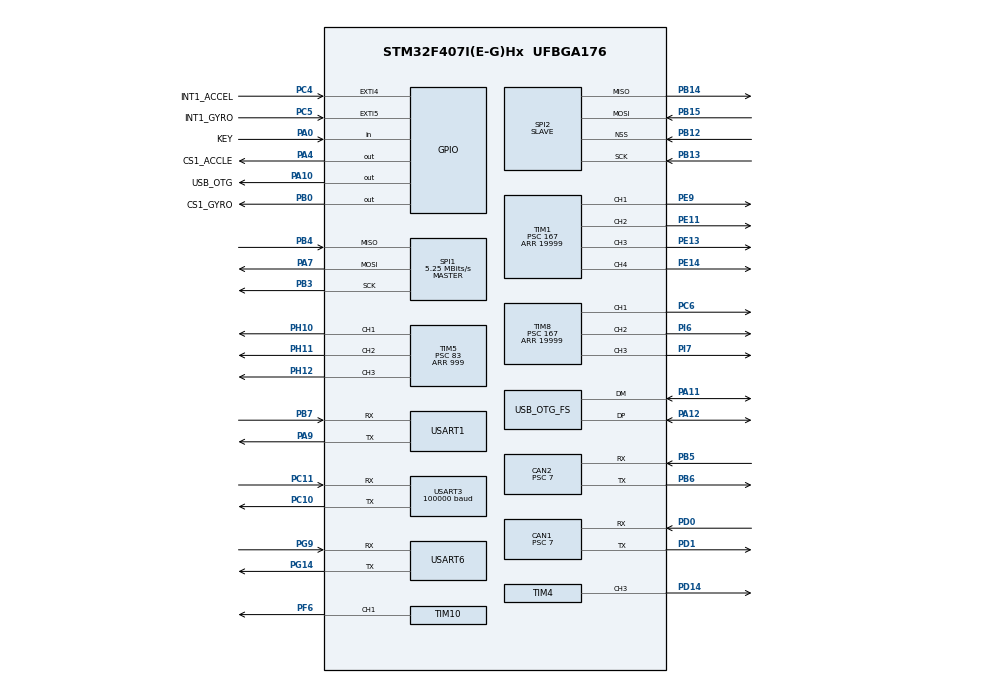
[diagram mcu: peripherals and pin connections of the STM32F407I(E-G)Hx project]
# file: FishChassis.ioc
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CAN1.BS1=CAN_BS1_4TQ
CAN1.CalculateBaudRate=999999
CAN1.CalculateTimeBit=1000
CAN1.CalculateTimeQuantum=166.66666666666669
CAN1.Prescaler=7
CAN2.BS1=CAN_BS1_4TQ
CAN2.CalculateBaudRate=999999
CAN2.CalculateTimeBit=1000
CAN2.CalculateTimeQuantum=166.66666666666669
CAN2.Prescaler=7
Dma.Request0=USART1_RX
Dma.Request1=USART1_TX
Dma.Request2=USART6_RX
Dma.Request3=USART6_TX
Dma.Request4=SPI2_RX
Dma.Request5=SPI2_TX
Dma.Request6=USART3_RX
Dma.SPI2_RX.4.Direction=DMA_PERIPH_TO_MEMORY
Dma.SPI2_RX.4.FIFOMode=DMA_FIFOMODE_DISABLE
Dma.SPI2_RX.4.Instance=DMA1_Stream3
Dma.SPI2_RX.4.MemDataAlignment=DMA_MDATAALIGN_BYTE
Dma.SPI2_RX.4.MemInc=DMA_MINC_ENABLE
Dma.SPI2_RX.4.Mode=DMA_NORMAL
Dma.SPI2_RX.4.PeriphDataAlignment=DMA_PDATAALIGN_BYTE
Dma.SPI2_RX.4.PeriphInc=DMA_PINC_DISABLE
Dma.SPI2_RX.4.Priority=DMA_PRIORITY_LOW
Dma.SPI2_TX.5.Direction=DMA_MEMORY_TO_PERIPH
Dma.SPI2_TX.5.FIFOMode=DMA_FIFOMODE_DISABLE
Dma.SPI2_TX.5.Instance=DMA1_Stream4
Dma.SPI2_TX.5.MemDataAlignment=DMA_MDATAALIGN_BYTE
Dma.SPI2_TX.5.MemInc=DMA_MINC_ENABLE
Dma.SPI2_TX.5.Mode=DMA_NORMAL
Dma.SPI2_TX.5.PeriphDataAlignment=DMA_PDATAALIGN_BYTE
Dma.SPI2_TX.5.PeriphInc=DMA_PINC_DISABLE
Dma.SPI2_TX.5.Priority=DMA_PRIORITY_LOW
Dma.USART1_RX.0.Direction=DMA_PERIPH_TO_MEMORY
Dma.USART1_RX.0.FIFOMode=DMA_FIFOMODE_DISABLE
Dma.USART1_RX.0.Instance=DMA2_Stream2
Dma.USART1_RX.0.MemDataAlignment=DMA_MDATAALIGN_BYTE
Dma.USART1_RX.0.MemInc=DMA_MINC_ENABLE
Dma.USART1_RX.0.Mode=DMA_NORMAL
Dma.USART1_RX.0.PeriphDataAlignment=DMA_PDATAALIGN_BYTE
Dma.USART1_RX.0.PeriphInc=DMA_PINC_DISABLE
Dma.USART1_RX.0.Priority=DMA_PRIORITY_LOW
Dma.USART1_TX.1.Direction=DMA_MEMORY_TO_PERIPH
Dma.USART1_TX.1.FIFOMode=DMA_FIFOMODE_DISABLE
Dma.USART1_TX.1.Instance=DMA2_Stream7
Dma.USART1_TX.1.MemDataAlignment=DMA_MDATAALIGN_BYTE
Dma.USART1_TX.1.MemInc=DMA_MINC_ENABLE
Dma.USART1_TX.1.Mode=DMA_NORMAL
Dma.USART1_TX.1.PeriphDataAlignment=DMA_PDATAALIGN_BYTE
Dma.USART1_TX.1.PeriphInc=DMA_PINC_DISABLE
Dma.USART1_TX.1.Priority=DMA_PRIORITY_LOW
Dma.USART3_RX.6.Direction=DMA_PERIPH_TO_MEMORY
Dma.USART3_RX.6.FIFOMode=DMA_FIFOMODE_DISABLE
Dma.USART3_RX.6.Instance=DMA1_Stream1
Dma.USART3_RX.6.MemDataAlignment=DMA_MDATAALIGN_BYTE
Dma.USART3_RX.6.MemInc=DMA_MINC_ENABLE
Dma.USART3_RX.6.Mode=DMA_NORMAL
Dma.USART3_RX.6.PeriphDataAlignment=DMA_PDATAALIGN_BYTE
Dma.USART3_RX.6.PeriphInc=DMA_PINC_DISABLE
Dma.USART3_RX.6.Priority=DMA_PRIORITY_LOW
Dma.USART6_RX.2.Direction=DMA_PERIPH_TO_MEMORY
Dma.USART6_RX.2.FIFOMode=DMA_FIFOMODE_DISABLE
Dma.USART6_RX.2.Instance=DMA2_Stream1
Dma.USART6_RX.2.MemDataAlignment=DMA_MDATAALIGN_BYTE
Dma.USART6_RX.2.MemInc=DMA_MINC_ENABLE
Dma.USART6_RX.2.Mode=DMA_NORMAL
Dma.USART6_RX.2.PeriphDataAlignment=DMA_PDATAALIGN_BYTE
Dma.USART6_RX.2.PeriphInc=DMA_PINC_DISABLE
Dma.USART6_RX.2.Priority=DMA_PRIORITY_LOW
Dma.USART6_TX.3.Direction=DMA_MEMORY_TO_PERIPH
Dma.USART6_TX.3.FIFOMode=DMA_FIFOMODE_DISABLE
Dma.USART6_TX.3.Instance=DMA2_Stream6
Dma.USART6_TX.3.MemDataAlignment=DMA_MDATAALIGN_BYTE
Dma.USART6_TX.3.MemInc=DMA_MINC_ENABLE
Dma.USART6_TX.3.Mode=DMA_NORMAL
Dma.USART6_TX.3.PeriphDataAlignment=DMA_PDATAALIGN_BYTE
Dma.USART6_TX.3.PeriphInc=DMA_PINC_DISABLE
Dma.USART6_TX.3.Priority=DMA_PRIORITY_LOW
Mcu.Family=STM32F4
Mcu.Name=STM32F407I(E-G)Hx
Mcu.Package=UFBGA176
NVIC.CAN1_RX0_IRQn=true\:0\:0\:false\:false\:true\:false\:true\:true\:true
NVIC.CAN2_RX1_IRQn=true\:0\:0\:false\:false\:true\:false\:true\:true\:true
NVIC.DMA1_Stream1_IRQn=true\:0\:0\:false\:false\:true\:true\:false\:true\:true
NVIC.DMA1_Stream3_IRQn=true\:0\:0\:false\:false\:true\:true\:false\:true\:true
NVIC.DMA1_Stream4_IRQn=true\:0\:0\:false\:false\:true\:true\:false\:true\:true
NVIC.DMA2_Stream1_IRQn=true\:0\:0\:false\:false\:true\:true\:false\:true\:true
NVIC.DMA2_Stream2_IRQn=true\:0\:0\:false\:false\:true\:true\:false\:true\:true
NVIC.DMA2_Stream6_IRQn=true\:0\:0\:false\:false\:true\:true\:false\:true\:true
NVIC.DMA2_Stream7_IRQn=true\:0\:0\:false\:false\:true\:true\:false\:true\:true
NVIC.EXTI4_IRQn=true\:0\:0\:false\:false\:false\:false\:true\:true\:false
NVIC.EXTI9_5_IRQn=true\:0\:0\:false\:false\:false\:false\:true\:true\:false
NVIC.OTG_FS_IRQn=true\:0\:0\:false\:false\:true\:false\:true\:true\:true
NVIC.PriorityGroup=NVIC_PRIORITYGROUP_4
NVIC.SPI2_IRQn=true\:0\:0\:false\:false\:true\:false\:true\:true\:true
NVIC.TIM8_TRG_COM_TIM14_IRQn=true\:15\:0\:false\:false\:false\:false\:false\:true\:true
NVIC.TimeBase=TIM8_TRG_COM_TIM14_IRQn
NVIC.TimeBaseIP=TIM14
NVIC.USART1_IRQn=true\:0\:0\:false\:false\:true\:false\:true\:true\:true
NVIC.USART3_IRQn=true\:0\:0\:false\:false\:true\:false\:true\:true\:true
NVIC.USART6_IRQn=true\:0\:0\:false\:false\:true\:false\:true\:true\:true
PA0-WKUP.GPIO_Label=KEY
PA0-WKUP.Signal=GPIO_Input
PA10.GPIO_Label=USB_OTG
PA10.PinState=GPIO_PIN_SET
PA10.Signal=GPIO_Output
PA11.Mode=Device_Only
PA11.Signal=USB_OTG_FS_DM
PA12.Mode=Device_Only
PA12.Signal=USB_OTG_FS_DP
PA13.Mode=Serial_Wire
PA13.Signal=SYS_JTMS-SWDIO
PA14.Mode=Serial_Wire
PA14.Signal=SYS_JTCK-SWCLK
PA4.GPIO_Label=CS1_ACCLE
PA4.GPIO_PuPd=GPIO_PULLUP
PA4.GPIO_Speed=GPIO_SPEED_FREQ_VERY_HIGH
PA4.PinState=GPIO_PIN_SET
PA4.Signal=GPIO_Output
PA7.Mode=Full_Duplex_Master
PA7.Signal=SPI1_MOSI
PA9.Mode=Asynchronous
PA9.Signal=USART1_TX
PB0.GPIO_Label=CS1_GYRO
PB0.GPIO_PuPd=GPIO_PULLUP
PB0.GPIO_Speed=GPIO_SPEED_FREQ_VERY_HIGH
PB0.PinState=GPIO_PIN_SET
PB0.Signal=GPIO_Output
PB12.Mode=NSS_Signal_Hard_Input
PB12.Signal=SPI2_NSS
PB13.Mode=Full_Duplex_Slave
PB13.Signal=SPI2_SCK
PB14.Mode=Full_Duplex_Slave
PB14.Signal=SPI2_MISO
PB15.Mode=Full_Duplex_Slave
PB15.Signal=SPI2_MOSI
PB3.Mode=Full_Duplex_Master
PB3.Signal=SPI1_SCK
PB4.Mode=Full_Duplex_Master
PB4.Signal=SPI1_MISO
PB5.Mode=CAN_Activate
PB5.Signal=CAN2_RX
PB6.Mode=CAN_Activate
PB6.Signal=CAN2_TX
PB7.Mode=Asynchronous
PB7.Signal=USART1_RX
PC10.Mode=Asynchronous
PC10.Signal=USART3_TX
PC11.Mode=Asynchronous
PC11.Signal=USART3_RX
PC4.GPIO_Label=INT1_ACCEL
PC4.GPIO_ModeDefaultEXTI=GPIO_MODE_IT_FALLING
PC4.Signal=GPXTI4
PC5.GPIO_Label=INT1_GYRO
PC5.GPIO_ModeDefaultEXTI=GPIO_MODE_IT_FALLING
PC5.Signal=GPXTI5
PC6.Signal=S_TIM8_CH1
PD0.Mode=CAN_Activate
PD0.Signal=CAN1_RX
PD1.Mode=CAN_Activate
PD1.Signal=CAN1_TX
PD14.Signal=S_TIM4_CH3
PE11.Signal=S_TIM1_CH2
PE13.Signal=S_TIM1_CH3
PE14.Signal=S_TIM1_CH4
PE9.Signal=S_TIM1_CH1
PF6.Signal=S_TIM10_CH1
PG14.Mode=Asynchronous
PG14.Signal=USART6_TX
PG9.Mode=Asynchronous
PG9.Signal=USART6_RX
PH0-OSC_IN.Mode=HSE-External-Oscillator
PH0-OSC_IN.Signal=RCC_OSC_IN
PH1-OSC_OUT.Mode=HSE-External-Oscillator
PH1-OSC_OUT.Signal=RCC_OSC_OUT
PH10.Signal=S_TIM5_CH1
PH11.Signal=S_TIM5_CH2
PH12.Signal=S_TIM5_CH3
PI6.Signal=S_TIM8_CH2
PI7.Signal=S_TIM8_CH3
ProjectManager.HeapSize=0x200
ProjectManager.StackSize=0x400
ProjectManager.TargetToolchain=STM32CubeIDE
RCC.48MHZClocksFreq_Value=48000000
RCC.AHBFreq_Value=168000000
RCC.APB1CLKDivider=RCC_HCLK_DIV4
RCC.APB1Freq_Value=42000000
RCC.APB1TimFreq_Value=84000000
RCC.APB2CLKDivider=RCC_HCLK_DIV2
RCC.APB2Freq_Value=84000000
RCC.APB2TimFreq_Value=168000000
RCC.CortexFreq_Value=168000000
RCC.HCLKFreq_Value=168000000
RCC.HSE_VALUE=12000000
RCC.HSI_VALUE=16000000
RCC.LSE_VALUE=32768
RCC.PLLM=6
RCC.PLLN=168
RCC.PLLQ=7
RCC.SYSCLKFreq_VALUE=168000000
RCC.SYSCLKSource=RCC_SYSCLKSOURCE_PLLCLK
RCC.VCOOutputFreq_Value=336000000
SH.S_TIM10_CH1.0=TIM10_CH1,PWM Generation1 CH1
SH.S_TIM1_CH1.0=TIM1_CH1,PWM Generation1 CH1
SH.S_TIM1_CH2.0=TIM1_CH2,PWM Generation2 CH2
SH.S_TIM1_CH3.0=TIM1_CH3,PWM Generation3 CH3
SH.S_TIM1_CH4.0=TIM1_CH4,PWM Generation4 CH4
SH.S_TIM4_CH3.0=TIM4_CH3,PWM Generation3 CH3
SH.S_TIM5_CH1.0=TIM5_CH1,PWM Generation1 CH1
SH.S_TIM5_CH2.0=TIM5_CH2,PWM Generation2 CH2
SH.S_TIM5_CH3.0=TIM5_CH3,PWM Generation3 CH3
SH.S_TIM8_CH1.0=TIM8_CH1,PWM Generation1 CH1
SH.S_TIM8_CH2.0=TIM8_CH2,PWM Generation2 CH2
SH.S_TIM8_CH3.0=TIM8_CH3,PWM Generation3 CH3
SPI1.BaudRatePrescaler=SPI_BAUDRATEPRESCALER_16
SPI1.CLKPhase=SPI_PHASE_2EDGE
SPI1.CLKPolarity=SPI_POLARITY_HIGH
SPI1.CalculateBaudRate=5.25 MBits/s
SPI1.Direction=SPI_DIRECTION_2LINES
SPI1.Mode=SPI_MODE_MASTER
SPI1.VirtualType=VM_MASTER
SPI2.Direction=SPI_DIRECTION_2LINES
SPI2.Mode=SPI_MODE_SLAVE
SPI2.VirtualNSS=VM_NSSHARD
SPI2.VirtualType=VM_SLAVE
STMicroelectronics.X-CUBE-AZRTOS-F4.1.1.0.TX_APP_MEM_POOL_SIZE=4096
STMicroelectronics.X-CUBE-AZRTOS-F4.1.1.0.TX_DISABLE_PREEMPTION_THRESHOLD=0
STMicroelectronics.X-CUBE-AZRTOS-F4.1.1.0.TX_DISABLE_REDUNDANT_CLEARING=1
STMicroelectronics.X-CUBE-AZRTOS-F4.1.1.0.TX_DISABLE_STACK_FILLING=1
STMicroelectronics.X-CUBE-AZRTOS-F4.1.1.0.TX_ENABLE_EVENT_TRACE=1
STMicroelectronics.X-CUBE-AZRTOS-F4.1.1.0.TX_INLINE_THREAD_RESUME_SUSPEND=1
STMicroelectronics.X-CUBE-AZRTOS-F4.1.1.0.TX_MINIMUM_STACK=64
STMicroelectronics.X-CUBE-AZRTOS-F4.1.1.0.TX_REACTIVATE_INLINE=1
STMicroelectronics.X-CUBE-AZRTOS-F4.1.1.0.TX_TIMER_PROCESS_IN_ISR=1
STMicroelectronics.X-CUBE-AZRTOS-F4.1.1.0.TX_TIMER_TICKS_PER_SECOND=1000
STMicroelectronics.X-CUBE-AZRTOS-F4.1.1.0.ThreadXCcRTOSJjThreadXJjCore=true
STMicroelectronics.X-CUBE-AZRTOS-F4.1.1.0.ThreadXCcRTOSJjThreadXJjTraceXOosupport=true
STMicroelectronics.X-CUBE-AZRTOS-F4.1.1.0.USBD_CDCACM_EPINCMD_ADDR=2
STMicroelectronics.X-CUBE-AZRTOS-F4.1.1.0.USBD_CDCACM_EPIN_ADDR=3
STMicroelectronics.X-CUBE-AZRTOS-F4.1.1.0.USBD_SERIAL_NUMBER=CDC_ACM001
STMicroelectronics.X-CUBE-AZRTOS-F4.1.1.0.USBXCcUSBJjUSBXJjCoreSystem=true
STMicroelectronics.X-CUBE-AZRTOS-F4.1.1.0.USBXCcUSBJjUSBXJjTraceXOoSupport=true
STMicroelectronics.X-CUBE-AZRTOS-F4.1.1.0.USBXCcUSBJjUSBXJjUXOoDeviceOoClassOoCDCOoACM=true
STMicroelectronics.X-CUBE-AZRTOS-F4.1.1.0.USBXCcUSBJjUSBXJjUXOoDeviceOoControllers=true
STMicroelectronics.X-CUBE-AZRTOS-F4.1.1.0.USBXCcUSBJjUSBXJjUXOoDeviceOoCoreStack=true
STMicroelectronics.X-CUBE-AZRTOS-F4.1.1.0.UX_DEVICE_APP_MEM_POOL_SIZE=40960
STMicroelectronics.X-CUBE-AZRTOS-F4.1.1.0.UX_SLAVE_REQUEST_DATA_MAX_LENGTH=512
STMicroelectronics.X-CUBE-AZRTOS-F4.1.1.0_IsAnAzureRtosMw=true
TIM1.Channel-PWM\ Generation1\ CH1=TIM_CHANNEL_1
TIM1.Channel-PWM\ Generation2\ CH2=TIM_CHANNEL_2
TIM1.Channel-PWM\ Generation3\ CH3=TIM_CHANNEL_3
TIM1.Channel-PWM\ Generation4\ CH4=TIM_CHANNEL_4
TIM1.Period=19999
TIM1.Prescaler=167
TIM1.Pulse-PWM\ Generation1\ CH1=0
TIM1.Pulse-PWM\ Generation2\ CH2=0
TIM1.Pulse-PWM\ Generation3\ CH3=0
TIM1.Pulse-PWM\ Generation4\ CH4=0
TIM10.Channel=TIM_CHANNEL_1
TIM10.Period=1999
TIM10.Prescaler=83
TIM10.Pulse=499
TIM4.Channel-PWM\ Generation3\ CH3=TIM_CHANNEL_3
TIM4.Period=3999
TIM4.Prescaler=83
TIM5.Channel-PWM\ Generation1\ CH1=TIM_CHANNEL_1
TIM5.Channel-PWM\ Generation2\ CH2=TIM_CHANNEL_2
TIM5.Channel-PWM\ Generation3\ CH3=TIM_CHANNEL_3
TIM5.Period=999
TIM5.Prescaler=83
TIM5.Pulse-PWM\ Generation1\ CH1=0
TIM5.Pulse-PWM\ Generation2\ CH2=0
TIM5.Pulse-PWM\ Generation3\ CH3=0
TIM8.Channel-PWM\ Generation1\ CH1=TIM_CHANNEL_1
TIM8.Channel-PWM\ Generation2\ CH2=TIM_CHANNEL_2
TIM8.Channel-PWM\ Generation3\ CH3=TIM_CHANNEL_3
TIM8.Period=19999
TIM8.Prescaler=167
USART1.VirtualMode=VM_ASYNC
USART3.BaudRate=100000
USART3.Mode=MODE_RX
USART3.Parity=PARITY_EVEN
USART3.VirtualMode=VM_ASYNC
USART3.WordLength=WORDLENGTH_9B
USART6.VirtualMode=VM_ASYNC
USB_OTG_FS.VirtualMode=Device_Only
VP_STMicroelectronics.X-CUBE-AZRTOS-F4_VS_RTOSJjThreadX_6.1.10_1.1.0.Mode=RTOSJjThreadX
VP_STMicroelectronics.X-CUBE-AZRTOS-F4_VS_USBJjUSBX_6.1.10_1.1.0.Mode=USBJjUSBX
VP_SYS_VS_tim14.Mode=TIM14
VP_TIM10_VS_ClockSourceINT.Mode=Enable_Timer
VP_TIM1_VS_ClockSourceINT.Mode=Internal
VP_TIM4_VS_ClockSourceINT.Mode=Internal
VP_TIM5_VS_ClockSourceINT.Mode=Internal
VP_TIM8_VS_ClockSourceINT.Mode=Internal
board=custom

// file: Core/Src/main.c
/* USER CODE BEGIN Header */
/**
  ******************************************************************************
  * @file           : main.c
  * @brief          : Main program body
  ******************************************************************************
  * @attention
  *
  * Copyright (c) 2023 STMicroelectronics.
  * All rights reserved.
  *
  * This software is licensed under terms that can be found in the LICENSE file
  * in the root directory of this software component.
  * If no LICENSE file comes with this software, it is provided AS-IS.
  *
  ******************************************************************************
  */

/* USER CODE END Header */
#include "app_threadx.h"
#include "main.h"
#include "can.h"
#include "dma.h"
#include "spi.h"
#include "tim.h"
#include "usart.h"
#include "usb_otg.h"
#include "gpio.h"

/* USER CODE BEGIN Includes */
#include "arm_math.h"
/* USER CODE END Includes */

void SystemClock_Config(void);

int main(void)
{

  /* MCU Configuration--------------------------------------------------------*/

  /* Reset of all peripherals, Initializes the Flash interface and the Systick. */
  HAL_Init();

  /* Configure the system clock */
  SystemClock_Config();

  /* Initialize all configured peripherals */
  MX_GPIO_Init();
  MX_DMA_Init();
  MX_TIM1_Init();
  MX_TIM4_Init();
  MX_TIM5_Init();
  MX_TIM10_Init();
  MX_SPI1_Init();
  MX_SPI2_Init();
  MX_USART1_UART_Init();
  MX_USART3_UART_Init();
  MX_USART6_UART_Init();
  MX_CAN1_Init();
  MX_CAN2_Init();
  MX_USB_OTG_FS_PCD_Init();
  MX_TIM8_Init();

  MX_ThreadX_Init();

  /* We should never get here as control is now taken by the scheduler */
  /* Infinite loop */
    while (1) {

    }
}

void SystemClock_Config(void)
{
  LL_FLASH_SetLatency(LL_FLASH_LATENCY_5);
  while(LL_FLASH_GetLatency()!= LL_FLASH_LATENCY_5)
  {
  }
  LL_PWR_SetRegulVoltageScaling(LL_PWR_REGU_VOLTAGE_SCALE1);
  LL_RCC_HSE_Enable();

   /* Wait till HSE is ready */
  while(LL_RCC_HSE_IsReady() != 1)
  {

  }
  LL_RCC_PLL_ConfigDomain_SYS(LL_RCC_PLLSOURCE_HSE, LL_RCC_PLLM_DIV_6, 168, LL_RCC_PLLP_DIV_2);
  LL_RCC_PLL_ConfigDomain_48M(LL_RCC_PLLSOURCE_HSE, LL_RCC_PLLM_DIV_6, 168, LL_RCC_PLLQ_DIV_7);
  LL_RCC_PLL_Enable();

   /* Wait till PLL is ready */
  while(LL_RCC_PLL_IsReady() != 1)
  {

  }
  while (LL_PWR_IsActiveFlag_VOS() == 0)
  {
  }
  LL_RCC_SetAHBPrescaler(LL_RCC_SYSCLK_DIV_1);
  LL_RCC_SetAPB1Prescaler(LL_RCC_APB1_DIV_4);
  LL_RCC_SetAPB2Prescaler(LL_RCC_APB2_DIV_2);
  LL_RCC_SetSysClkSource(LL_RCC_SYS_CLKSOURCE_PLL);

   /* Wait till System clock is ready */
  while(LL_RCC_GetSysClkSource() != LL_RCC_SYS_CLKSOURCE_STATUS_PLL)
  {

  }
  LL_SetSystemCoreClock(168000000);

   /* Update the time base */
  if (HAL_InitTick (TICK_INT_PRIORITY) != HAL_OK)
  {
    Error_Handler();
  }
}

/* USER CODE BEGIN 4 */
void TIM8_TRG_COM_TIM14_IRQHandler(void) {
    uwTick += uwTickFreq;
    LL_TIM_ClearFlag_UPDATE(TIM14);
}
/* USER CODE END 4 */

void HAL_TIM_PeriodElapsedCallback(TIM_HandleTypeDef *htim)
{
  if (htim->Instance == TIM14) {
    HAL_IncTick();
  }
}

void Error_Handler(void)
{
    __disable_irq();
    while (1) {
    }
}
